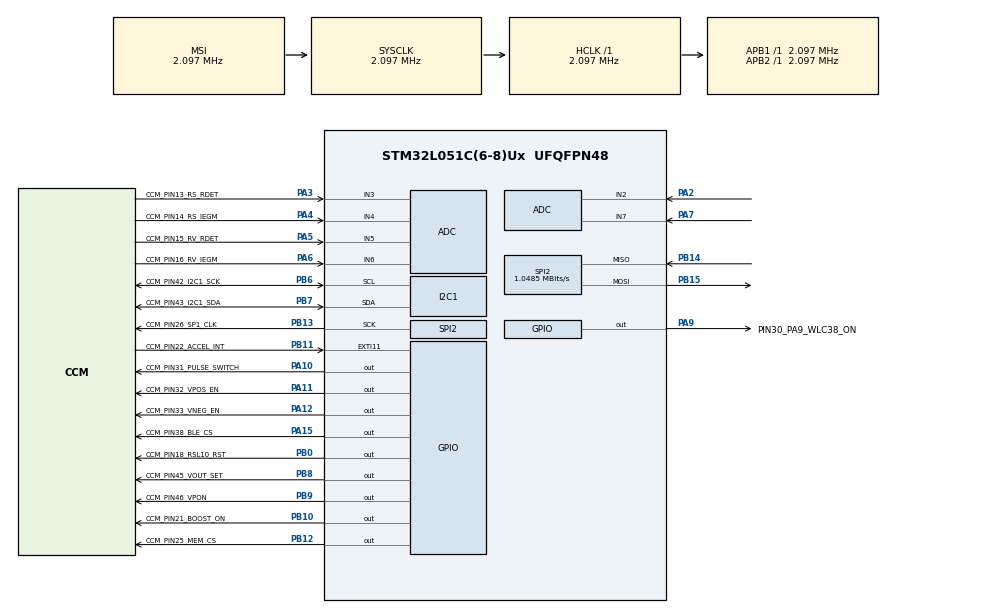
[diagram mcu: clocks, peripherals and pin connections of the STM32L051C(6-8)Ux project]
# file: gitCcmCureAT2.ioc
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ADC.ClockPrescaler=ADC_CLOCK_ASYNC_DIV64
ADC.ContinuousConvMode=ENABLE
ADC.SamplingTime=ADC_SAMPLETIME_160CYCLES_5
Mcu.Family=STM32L0
Mcu.Name=STM32L051C(6-8)Ux
Mcu.Package=UFQFPN48
NVIC.ADC1_COMP_IRQn=true\:0\:0\:false\:false\:true\:true\:true\:true
NVIC.EXTI4_15_IRQn=true\:0\:0\:false\:false\:true\:true\:true\:true
NVIC.RTC_IRQn=true\:0\:0\:false\:false\:true\:true\:true\:true
NVIC.SPI2_IRQn=true\:0\:0\:false\:false\:true\:true\:true\:true
NVIC.TIM6_DAC_IRQn=true\:1\:0\:true\:false\:true\:true\:true\:true
PA0.GPIO_Label=CCM_PIN10_WKUP_INTR
PA0.Mode=SYS_WakeUp0
PA0.Signal=SYS_WKUP1
PA10.GPIO_Label=CCM_PIN31_PULSE_SWITCH
PA10.GPIO_ModeDefaultOutputPP=GPIO_MODE_OUTPUT_OD
PA10.GPIO_PuPd=GPIO_NOPULL
PA10.GPIO_Speed=GPIO_SPEED_FREQ_VERY_HIGH
PA10.PinState=GPIO_PIN_SET
PA10.Signal=GPIO_Output
PA11.GPIO_Label=CCM_PIN32_VPOS_EN
PA11.GPIO_ModeDefaultOutputPP=GPIO_MODE_OUTPUT_PP
PA11.GPIO_PuPd=GPIO_NOPULL
PA11.GPIO_Speed=GPIO_SPEED_FREQ_VERY_HIGH
PA11.Signal=GPIO_Output
PA12.GPIO_Label=CCM_PIN33_VNEG_EN
PA12.GPIO_ModeDefaultOutputPP=GPIO_MODE_OUTPUT_PP
PA12.GPIO_PuPd=GPIO_NOPULL
PA12.GPIO_Speed=GPIO_SPEED_FREQ_VERY_HIGH
PA12.Signal=GPIO_Output
PA13.Mode=Serial_Wire
PA13.Signal=SYS_SWDIO
PA14.Mode=Serial_Wire
PA14.Signal=SYS_SWCLK
PA15.GPIO_Label=CCM_PIN38_BLE_CS
PA15.GPIO_PuPd=GPIO_PULLUP
PA15.GPIO_Speed=GPIO_SPEED_FREQ_LOW
PA15.PinState=GPIO_PIN_SET
PA15.Signal=GPIO_Output
PA2.Mode=IN2
PA2.Signal=ADC_IN2
PA3.GPIO_Label=CCM_PIN13_RS_RDET
PA3.Mode=IN3
PA3.Signal=ADC_IN3
PA4.GPIO_Label=CCM_PIN14_RS_IEGM
PA4.Mode=IN4
PA4.Signal=ADC_IN4
PA5.GPIO_Label=CCM_PIN15_RV_RDET
PA5.Mode=IN5
PA5.Signal=ADC_IN5
PA6.GPIO_Label=CCM_PIN16_RV_IEGM
PA6.Mode=IN6
PA6.Signal=ADC_IN6
PA7.Mode=IN7
PA7.Signal=ADC_IN7
PA9.GPIO_Label=PIN30_PA9_WLC38_ON
PA9.GPIO_ModeDefaultOutputPP=GPIO_MODE_OUTPUT_OD
PA9.GPIO_PuPd=GPIO_NOPULL
PA9.GPIO_Speed=GPIO_SPEED_FREQ_LOW
PA9.PinState=GPIO_PIN_SET
PA9.Signal=GPIO_Output
PB0.GPIO_Label=CCM_PIN18_RSL10_RST
PB0.GPIO_Speed=GPIO_SPEED_FREQ_LOW
PB0.PinState=GPIO_PIN_SET
PB0.Signal=GPIO_Output
PB10.GPIO_Label=CCM_PIN21_BOOST_ON
PB10.GPIO_ModeDefaultOutputPP=GPIO_MODE_OUTPUT_PP
PB10.GPIO_PuPd=GPIO_NOPULL
PB10.GPIO_Speed=GPIO_SPEED_FREQ_LOW
PB10.PinState=GPIO_PIN_SET
PB10.Signal=GPIO_Output
PB11.GPIO_Label=CCM_PIN22_ACCEL_INT
PB11.GPIO_PuPd=GPIO_PULLDOWN
PB11.Signal=GPXTI11
PB12.GPIO_Label=CCM_PIN25_MEM_CS
PB12.GPIO_PuPd=GPIO_PULLUP
PB12.GPIO_Speed=GPIO_SPEED_FREQ_LOW
PB12.PinState=GPIO_PIN_SET
PB12.Signal=GPIO_Output
PB13.GPIO_Label=CCM_PIN26_SP1_CLK
PB13.Mode=Full_Duplex_Master
PB13.Signal=SPI2_SCK
PB14.Mode=Full_Duplex_Master
PB14.Signal=SPI2_MISO
PB15.Mode=Full_Duplex_Master
PB15.Signal=SPI2_MOSI
PB6.GPIO_Label=CCM_PIN42_I2C1_SCK
PB6.Mode=I2C
PB6.Signal=I2C1_SCL
PB7.GPIO_Label=CCM_PIN43_I2C1_SDA
PB7.Mode=I2C
PB7.Signal=I2C1_SDA
PB8.GPIO_Label=CCM_PIN45_VOUT_SET
PB8.GPIO_PuPd=GPIO_PULLUP
PB8.GPIO_Speed=GPIO_SPEED_FREQ_LOW
PB8.PinState=GPIO_PIN_SET
PB8.Signal=GPIO_Output
PB9.GPIO_FM9=I2C_FASTMODEPLUS_PB9
PB9.GPIO_Label=CCM_PIN46_VPON
PB9.GPIO_ModeDefaultOutputPP=GPIO_MODE_OUTPUT_PP
PB9.GPIO_PuPd=GPIO_NOPULL
PB9.GPIO_Speed=GPIO_SPEED_FREQ_HIGH
PB9.PinState=GPIO_PIN_RESET
PB9.Signal=GPIO_Output
PC14-OSC32_IN.Mode=LSE-External-Oscillator
PC14-OSC32_IN.Signal=RCC_OSC32_IN
PC15-OSC32_OUT.Mode=LSE-External-Oscillator
PC15-OSC32_OUT.Signal=RCC_OSC32_OUT
ProjectManager.HeapSize=0x200
ProjectManager.StackSize=0x400
ProjectManager.TargetToolchain=STM32CubeIDE
RCC.AHBFreq_Value=2097000
RCC.APB1Freq_Value=2097000
RCC.APB1TimFreq_Value=2097000
RCC.APB2Freq_Value=2097000
RCC.APB2TimFreq_Value=2097000
RCC.HSE_VALUE=8000000
RCC.HSI16_VALUE=16000000
RCC.HSI_VALUE=16000000
RCC.MSI_VALUE=2097000
RCC.RTCClockSelection=RCC_RTCCLKSOURCE_LSE
RCC.RTCClockSelectionVirtual=RCC_RTCCLKSOURCE_LSE
RCC.SYSCLKFreq_VALUE=2097000
RCC.VCOOutputFreq_Value=48000000
RTC.Format=RTC_FORMAT_BIN
RTC.Hours=0
RTC.Month=RTC_MONTH_DECEMBER
RTC.StoreOperation=RTC_STOREOPERATION_SET
RTC.WakeUpClock-WakeUp=RTC_WAKEUPCLOCK_CK_SPRE_16BITS
RTC.WakeUpCounter-WakeUp=3
RTC.WeekDay=RTC_WEEKDAY_FRIDAY
RTC.Year=23
SPI2.CalculateBaudRate=1.0485 MBits/s
SPI2.Direction=SPI_DIRECTION_2LINES
SPI2.Mode=SPI_MODE_MASTER
SPI2.VirtualType=VM_MASTER
TIM6.Period=232
TIM6.Prescaler=44
VP_RTC_VS_RTC_Activate.Mode=RTC_Enabled
VP_RTC_VS_RTC_Calendar.Mode=RTC_Calendar
VP_RTC_VS_RTC_WakeUp_intern.Mode=WakeUp
VP_TIM6_VS_ClockSourceINT.Mode=Enable_Timer
board=custom

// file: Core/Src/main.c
/* USER CODE BEGIN Header */
/**
  ******************************************************************************
  * @file           : main.c
  * @brief          : Main program body
  ******************************************************************************
  * @attention
  *
  * Copyright (c) 2023 STMicroelectronics.
  * All rights reserved.
  *
  * This software is licensed under terms that can be found in the LICENSE file
  * in the root directory of this software component.
  * If no LICENSE file comes with this software, it is provided AS-IS.
  *
  ******************************************************************************
  */
/* USER CODE END Header */
#include "main.h"

ADC_HandleTypeDef hadc;

I2C_HandleTypeDef hi2c1;

RTC_HandleTypeDef hrtc;

SPI_HandleTypeDef hspi2;

TIM_HandleTypeDef htim6;

void SystemClock_Config(void);
static void MX_GPIO_Init(void);
static void MX_ADC_Init(void);
static void MX_I2C1_Init(void);
static void MX_RTC_Init(void);
static void MX_SPI2_Init(void);
static void MX_TIM6_Init(void);

/* USER CODE BEGIN 0 */

void main_adcConfigAllCh(void)
{
  MX_ADC_Init();
}

/* USER CODE END 0 */

int main(void)
{

  /* MCU Configuration--------------------------------------------------------*/

  /* Reset of all peripherals, Initializes the Flash interface and the Systick. */
  HAL_Init();

  /* Configure the system clock */
  SystemClock_Config();

  /* USER CODE BEGIN SysInit */

  // NOTE: MUST init before MX init
  mcu_sysInit();

  /* USER CODE END SysInit */

  /* Initialize all configured peripherals */
  MX_GPIO_Init();
  MX_ADC_Init();
  MX_I2C1_Init();
  MX_RTC_Init();
  MX_SPI2_Init();
  MX_TIM6_Init();
  /* USER CODE BEGIN 2 */

  // NOTE: MUST init after MX init(update MX init for out project)
  mcu_deviceInit();

  // start up mcu device interval
  mcu_startup();

  /* USER CODE END 2 */

  /* Infinite loop */
  /* USER CODE BEGIN WHILE */
  while (1)
  {
    /*
      1. mcu state machine process
      2. all device(chip) state machine in this;
    */
    mcu_allStateMachine();

    /* USER CODE END WHILE */

  }
}

void SystemClock_Config(void)
{
  RCC_OscInitTypeDef RCC_OscInitStruct = {0};
  RCC_ClkInitTypeDef RCC_ClkInitStruct = {0};
  RCC_PeriphCLKInitTypeDef PeriphClkInit = {0};

  /** Configure the main internal regulator output voltage
  */
  __HAL_PWR_VOLTAGESCALING_CONFIG(PWR_REGULATOR_VOLTAGE_SCALE1);

  /** Configure LSE Drive Capability
  */
  HAL_PWR_EnableBkUpAccess();
  __HAL_RCC_LSEDRIVE_CONFIG(RCC_LSEDRIVE_LOW);

  /** Initializes the RCC Oscillators according to the specified parameters
  * in the RCC_OscInitTypeDef structure.
  */
  RCC_OscInitStruct.OscillatorType = RCC_OSCILLATORTYPE_HSI|RCC_OSCILLATORTYPE_LSE
                              |RCC_OSCILLATORTYPE_MSI;
  RCC_OscInitStruct.LSEState = RCC_LSE_ON;
  RCC_OscInitStruct.HSIState = RCC_HSI_ON;
  RCC_OscInitStruct.HSICalibrationValue = RCC_HSICALIBRATION_DEFAULT;
  RCC_OscInitStruct.MSIState = RCC_MSI_ON;
  RCC_OscInitStruct.MSICalibrationValue = 0;
  RCC_OscInitStruct.MSIClockRange = RCC_MSIRANGE_5;
  RCC_OscInitStruct.PLL.PLLState = RCC_PLL_NONE;
  if (HAL_RCC_OscConfig(&RCC_OscInitStruct) != HAL_OK)
  {
    Error_Handler();
  }

  /** Initializes the CPU, AHB and APB buses clocks
  */
  RCC_ClkInitStruct.ClockType = RCC_CLOCKTYPE_HCLK|RCC_CLOCKTYPE_SYSCLK
                              |RCC_CLOCKTYPE_PCLK1|RCC_CLOCKTYPE_PCLK2;
  RCC_ClkInitStruct.SYSCLKSource = RCC_SYSCLKSOURCE_MSI;
  RCC_ClkInitStruct.AHBCLKDivider = RCC_SYSCLK_DIV1;
  RCC_ClkInitStruct.APB1CLKDivider = RCC_HCLK_DIV1;
  RCC_ClkInitStruct.APB2CLKDivider = RCC_HCLK_DIV1;

  if (HAL_RCC_ClockConfig(&RCC_ClkInitStruct, FLASH_LATENCY_0) != HAL_OK)
  {
    Error_Handler();
  }
  PeriphClkInit.PeriphClockSelection = RCC_PERIPHCLK_I2C1|RCC_PERIPHCLK_RTC;
  PeriphClkInit.I2c1ClockSelection = RCC_I2C1CLKSOURCE_PCLK1;
  PeriphClkInit.RTCClockSelection = RCC_RTCCLKSOURCE_LSE;
  if (HAL_RCCEx_PeriphCLKConfig(&PeriphClkInit) != HAL_OK)
  {
    Error_Handler();
  }
}

static void MX_ADC_Init(void)
{

  ADC_ChannelConfTypeDef sConfig = {0};

  /** Configure the global features of the ADC (Clock, Resolution, Data Alignment and number of conversion)
  */
  hadc.Instance = ADC1;
  hadc.Init.OversamplingMode = DISABLE;
  hadc.Init.ClockPrescaler = ADC_CLOCK_ASYNC_DIV64;
  hadc.Init.Resolution = ADC_RESOLUTION_12B;
  hadc.Init.SamplingTime = ADC_SAMPLETIME_160CYCLES_5;
  hadc.Init.ScanConvMode = ADC_SCAN_DIRECTION_FORWARD;
  hadc.Init.DataAlign = ADC_DATAALIGN_RIGHT;
  hadc.Init.ContinuousConvMode = ENABLE;
  hadc.Init.DiscontinuousConvMode = DISABLE;
  hadc.Init.ExternalTrigConvEdge = ADC_EXTERNALTRIGCONVEDGE_NONE;
  hadc.Init.ExternalTrigConv = ADC_SOFTWARE_START;
  hadc.Init.DMAContinuousRequests = DISABLE;
  hadc.Init.EOCSelection = ADC_EOC_SINGLE_CONV;
  hadc.Init.Overrun = ADC_OVR_DATA_PRESERVED;
  hadc.Init.LowPowerAutoWait = DISABLE;
  hadc.Init.LowPowerFrequencyMode = ENABLE;
  hadc.Init.LowPowerAutoPowerOff = DISABLE;
  if (HAL_ADC_Init(&hadc) != HAL_OK)
  {
    Error_Handler();
  }

  /** Configure for the selected ADC regular channel to be converted.
  */
  sConfig.Channel = ADC_CHANNEL_2;
  sConfig.Rank = ADC_RANK_CHANNEL_NUMBER;
  if (HAL_ADC_ConfigChannel(&hadc, &sConfig) != HAL_OK)
  {
    Error_Handler();
  }

  /** Configure for the selected ADC regular channel to be converted.
  */
  sConfig.Channel = ADC_CHANNEL_3;
  if (HAL_ADC_ConfigChannel(&hadc, &sConfig) != HAL_OK)
  {
    Error_Handler();
  }

  /** Configure for the selected ADC regular channel to be converted.
  */
  sConfig.Channel = ADC_CHANNEL_4;
  if (HAL_ADC_ConfigChannel(&hadc, &sConfig) != HAL_OK)
  {
    Error_Handler();
  }

  /** Configure for the selected ADC regular channel to be converted.
  */
  sConfig.Channel = ADC_CHANNEL_5;
  if (HAL_ADC_ConfigChannel(&hadc, &sConfig) != HAL_OK)
  {
    Error_Handler();
  }

  /** Configure for the selected ADC regular channel to be converted.
  */
  sConfig.Channel = ADC_CHANNEL_6;
  if (HAL_ADC_ConfigChannel(&hadc, &sConfig) != HAL_OK)
  {
    Error_Handler();
  }

  /** Configure for the selected ADC regular channel to be converted.
  */
  sConfig.Channel = ADC_CHANNEL_7;
  if (HAL_ADC_ConfigChannel(&hadc, &sConfig) != HAL_OK)
  {
    Error_Handler();
  }
  /* USER CODE BEGIN ADC_Init 2 */

  HAL_ADCEx_Calibration_Start(&hadc, ADC_SINGLE_ENDED);

  /* USER CODE END ADC_Init 2 */

}

static void MX_I2C1_Init(void)
{

  hi2c1.Instance = I2C1;
  hi2c1.Init.Timing = 0x00000708;
  hi2c1.Init.OwnAddress1 = 0;
  hi2c1.Init.AddressingMode = I2C_ADDRESSINGMODE_7BIT;
  hi2c1.Init.DualAddressMode = I2C_DUALADDRESS_DISABLE;
  hi2c1.Init.OwnAddress2 = 0;
  hi2c1.Init.OwnAddress2Masks = I2C_OA2_NOMASK;
  hi2c1.Init.GeneralCallMode = I2C_GENERALCALL_DISABLE;
  hi2c1.Init.NoStretchMode = I2C_NOSTRETCH_DISABLE;
  if (HAL_I2C_Init(&hi2c1) != HAL_OK)
  {
    Error_Handler();
  }

  /** Configure Analogue filter
  */
  if (HAL_I2CEx_ConfigAnalogFilter(&hi2c1, I2C_ANALOGFILTER_ENABLE) != HAL_OK)
  {
    Error_Handler();
  }

  /** Configure Digital filter
  */
  if (HAL_I2CEx_ConfigDigitalFilter(&hi2c1, 0) != HAL_OK)
  {
    Error_Handler();
  }

}

static void MX_RTC_Init(void)
{

  RTC_TimeTypeDef sTime = {0};
  RTC_DateTypeDef sDate = {0};

  /** Initialize RTC Only
  */
  hrtc.Instance = RTC;
  hrtc.Init.HourFormat = RTC_HOURFORMAT_24;
  hrtc.Init.AsynchPrediv = 127;
  hrtc.Init.SynchPrediv = 255;
  hrtc.Init.OutPut = RTC_OUTPUT_DISABLE;
  hrtc.Init.OutPutRemap = RTC_OUTPUT_REMAP_NONE;
  hrtc.Init.OutPutPolarity = RTC_OUTPUT_POLARITY_HIGH;
  hrtc.Init.OutPutType = RTC_OUTPUT_TYPE_OPENDRAIN;
  if (HAL_RTC_Init(&hrtc) != HAL_OK)
  {
    Error_Handler();
  }

  /** Initialize RTC and set the Time and Date
  */
  sTime.Hours = 0;
  sTime.Minutes = 0;
  sTime.Seconds = 0;
  sTime.DayLightSaving = RTC_DAYLIGHTSAVING_NONE;
  sTime.StoreOperation = RTC_STOREOPERATION_SET;
  if (HAL_RTC_SetTime(&hrtc, &sTime, RTC_FORMAT_BIN) != HAL_OK)
  {
    Error_Handler();
  }
  sDate.WeekDay = RTC_WEEKDAY_FRIDAY;
  sDate.Month = RTC_MONTH_DECEMBER;
  sDate.Date = 1;
  sDate.Year = 23;

  if (HAL_RTC_SetDate(&hrtc, &sDate, RTC_FORMAT_BIN) != HAL_OK)
  {
    Error_Handler();
  }

  /** Enable the WakeUp
  */
  if (HAL_RTCEx_SetWakeUpTimer_IT(&hrtc, 3, RTC_WAKEUPCLOCK_CK_SPRE_16BITS) != HAL_OK)
  {
    Error_Handler();
  }
  /* USER CODE BEGIN RTC_Init 2 */

  // Now we dont enter this mode, closed the counter.
  HAL_RTCEx_DeactivateWakeUpTimer(&hrtc);

/*
  hrtc.Init.OutPut = RTC_OUTPUT_WAKEUP;
  if (HAL_RTC_Init(&hrtc) != HAL_OK){
    Error_Handler();
  }
*/
  /* USER CODE END RTC_Init 2 */

}

static void MX_SPI2_Init(void)
{

  /* SPI2 parameter configuration*/
  hspi2.Instance = SPI2;
  hspi2.Init.Mode = SPI_MODE_MASTER;
  hspi2.Init.Direction = SPI_DIRECTION_2LINES;
  hspi2.Init.DataSize = SPI_DATASIZE_8BIT;
  hspi2.Init.CLKPolarity = SPI_POLARITY_LOW;
  hspi2.Init.CLKPhase = SPI_PHASE_1EDGE;
  hspi2.Init.NSS = SPI_NSS_SOFT;
  hspi2.Init.BaudRatePrescaler = SPI_BAUDRATEPRESCALER_2;
  hspi2.Init.FirstBit = SPI_FIRSTBIT_MSB;
  hspi2.Init.TIMode = SPI_TIMODE_DISABLE;
  hspi2.Init.CRCCalculation = SPI_CRCCALCULATION_DISABLE;
  hspi2.Init.CRCPolynomial = 7;
  if (HAL_SPI_Init(&hspi2) != HAL_OK)
  {
    Error_Handler();
  }

}

static void MX_TIM6_Init(void)
{

  TIM_MasterConfigTypeDef sMasterConfig = {0};

  htim6.Instance = TIM6;
  htim6.Init.Prescaler = 44;
  htim6.Init.CounterMode = TIM_COUNTERMODE_UP;
  htim6.Init.Period = 232;
  htim6.Init.AutoReloadPreload = TIM_AUTORELOAD_PRELOAD_DISABLE;
  if (HAL_TIM_Base_Init(&htim6) != HAL_OK)
  {
    Error_Handler();
  }
  sMasterConfig.MasterOutputTrigger = TIM_TRGO_RESET;
  sMasterConfig.MasterSlaveMode = TIM_MASTERSLAVEMODE_DISABLE;
  if (HAL_TIMEx_MasterConfigSynchronization(&htim6, &sMasterConfig) != HAL_OK)
  {
    Error_Handler();
  }

}

static void MX_GPIO_Init(void)
{
  GPIO_InitTypeDef GPIO_InitStruct = {0};

  /* GPIO Ports Clock Enable */
  __HAL_RCC_GPIOC_CLK_ENABLE();
  __HAL_RCC_GPIOA_CLK_ENABLE();
  __HAL_RCC_GPIOB_CLK_ENABLE();

  /*Configure GPIO pin Output Level */
  HAL_GPIO_WritePin(GPIOB, CCM_PIN18_RSL10_RST_Pin|CCM_PIN21_BOOST_ON_Pin|CCM_PIN25_MEM_CS_Pin|CCM_PIN45_VOUT_SET_Pin, GPIO_PIN_SET);

  /*Configure GPIO pin Output Level */
  HAL_GPIO_WritePin(GPIOA, PIN30_PA9_WLC38_ON_Pin|CCM_PIN31_PULSE_SWITCH_Pin|CCM_PIN38_BLE_CS_Pin, GPIO_PIN_SET);

  /*Configure GPIO pin Output Level */
  HAL_GPIO_WritePin(GPIOA, CCM_PIN32_VPOS_EN_Pin|CCM_PIN33_VNEG_EN_Pin, GPIO_PIN_RESET);

  /*Configure GPIO pin Output Level */
  HAL_GPIO_WritePin(CCM_PIN46_VPON_GPIO_Port, CCM_PIN46_VPON_Pin, GPIO_PIN_RESET);

  /*Configure GPIO pins : CCM_PIN18_RSL10_RST_Pin CCM_PIN21_BOOST_ON_Pin */
  GPIO_InitStruct.Pin = CCM_PIN18_RSL10_RST_Pin|CCM_PIN21_BOOST_ON_Pin;
  GPIO_InitStruct.Mode = GPIO_MODE_OUTPUT_PP;
  GPIO_InitStruct.Pull = GPIO_NOPULL;
  GPIO_InitStruct.Speed = GPIO_SPEED_FREQ_LOW;
  HAL_GPIO_Init(GPIOB, &GPIO_InitStruct);

  /*Configure GPIO pin : CCM_PIN22_ACCEL_INT_Pin */
  GPIO_InitStruct.Pin = CCM_PIN22_ACCEL_INT_Pin;
  GPIO_InitStruct.Mode = GPIO_MODE_IT_RISING;
  GPIO_InitStruct.Pull = GPIO_PULLDOWN;
  HAL_GPIO_Init(CCM_PIN22_ACCEL_INT_GPIO_Port, &GPIO_InitStruct);

  /*Configure GPIO pins : CCM_PIN25_MEM_CS_Pin CCM_PIN45_VOUT_SET_Pin */
  GPIO_InitStruct.Pin = CCM_PIN25_MEM_CS_Pin|CCM_PIN45_VOUT_SET_Pin;
  GPIO_InitStruct.Mode = GPIO_MODE_OUTPUT_PP;
  GPIO_InitStruct.Pull = GPIO_PULLUP;
  GPIO_InitStruct.Speed = GPIO_SPEED_FREQ_LOW;
  HAL_GPIO_Init(GPIOB, &GPIO_InitStruct);

  /*Configure GPIO pin : PIN30_PA9_WLC38_ON_Pin */
  GPIO_InitStruct.Pin = PIN30_PA9_WLC38_ON_Pin;
  GPIO_InitStruct.Mode = GPIO_MODE_OUTPUT_OD;
  GPIO_InitStruct.Pull = GPIO_NOPULL;
  GPIO_InitStruct.Speed = GPIO_SPEED_FREQ_LOW;
  HAL_GPIO_Init(PIN30_PA9_WLC38_ON_GPIO_Port, &GPIO_InitStruct);

  /*Configure GPIO pin : CCM_PIN31_PULSE_SWITCH_Pin */
  GPIO_InitStruct.Pin = CCM_PIN31_PULSE_SWITCH_Pin;
  GPIO_InitStruct.Mode = GPIO_MODE_OUTPUT_OD;
  GPIO_InitStruct.Pull = GPIO_NOPULL;
  GPIO_InitStruct.Speed = GPIO_SPEED_FREQ_VERY_HIGH;
  HAL_GPIO_Init(CCM_PIN31_PULSE_SWITCH_GPIO_Port, &GPIO_InitStruct);

  /*Configure GPIO pins : CCM_PIN32_VPOS_EN_Pin CCM_PIN33_VNEG_EN_Pin */
  GPIO_InitStruct.Pin = CCM_PIN32_VPOS_EN_Pin|CCM_PIN33_VNEG_EN_Pin;
  GPIO_InitStruct.Mode = GPIO_MODE_OUTPUT_PP;
  GPIO_InitStruct.Pull = GPIO_NOPULL;
  GPIO_InitStruct.Speed = GPIO_SPEED_FREQ_VERY_HIGH;
  HAL_GPIO_Init(GPIOA, &GPIO_InitStruct);

  /*Configure GPIO pin : CCM_PIN38_BLE_CS_Pin */
  GPIO_InitStruct.Pin = CCM_PIN38_BLE_CS_Pin;
  GPIO_InitStruct.Mode = GPIO_MODE_OUTPUT_PP;
  GPIO_InitStruct.Pull = GPIO_PULLUP;
  GPIO_InitStruct.Speed = GPIO_SPEED_FREQ_LOW;
  HAL_GPIO_Init(CCM_PIN38_BLE_CS_GPIO_Port, &GPIO_InitStruct);

  /*Configure GPIO pin : CCM_PIN46_VPON_Pin */
  GPIO_InitStruct.Pin = CCM_PIN46_VPON_Pin;
  GPIO_InitStruct.Mode = GPIO_MODE_OUTPUT_PP;
  GPIO_InitStruct.Pull = GPIO_NOPULL;
  GPIO_InitStruct.Speed = GPIO_SPEED_FREQ_HIGH;
  HAL_GPIO_Init(CCM_PIN46_VPON_GPIO_Port, &GPIO_InitStruct);

  /**/
  HAL_I2CEx_EnableFastModePlus(I2C_FASTMODEPLUS_PB9);

  /* EXTI interrupt init*/
  HAL_NVIC_SetPriority(EXTI4_15_IRQn, 0, 0);
  HAL_NVIC_EnableIRQ(EXTI4_15_IRQn);

}

void Error_Handler(void)
{
  __disable_irq();
  while (1)
  {
  }
}
